# SERDES_10G0 register map
Vendor: Texas Instruments
Registers are 32-bit, access per field, reset 0x0 unless marked. A register's access mark holds for its fields unless they carry their own. Offsets are as the file gives them; [hi:lo] are bit positions.

## SERDES_10G0 (part 7 of 8)
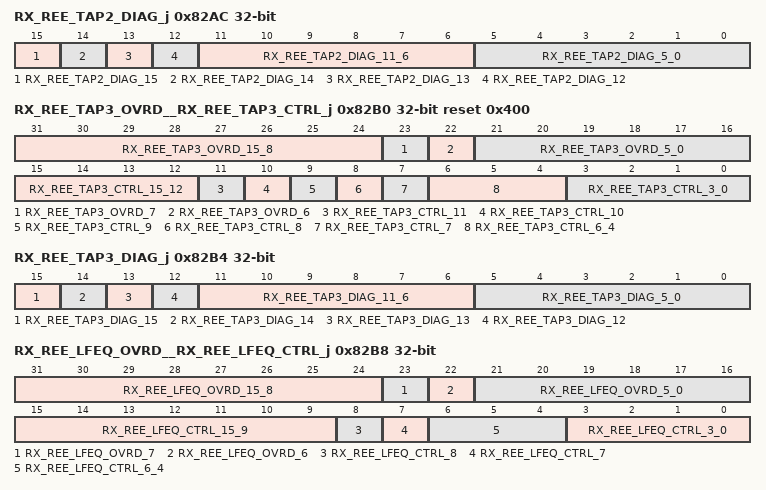
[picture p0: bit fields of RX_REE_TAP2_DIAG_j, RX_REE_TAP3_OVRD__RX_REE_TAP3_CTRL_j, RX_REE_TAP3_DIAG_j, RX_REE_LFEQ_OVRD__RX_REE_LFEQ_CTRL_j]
0x82AC RX_REE_TAP2_DIAG_j — REE tap 2 diagnostics register Offset = 82ACh + (j * 400h); where j = 0h to 3h
  [15] RX_REE_TAP2_DIAG_15 ro — Reserved
  [14] RX_REE_TAP2_DIAG_14 rw — Voter override neg : Writing a 1'b1 in this register bit will force the tap voter function to activate the voter neg signal for a single clock cycle.
  [13] RX_REE_TAP2_DIAG_13 rw — Voter override pos : Writing a 1'b1 in this register bit will force the tap voter function to activate the voter pos signal for a single clock cycle.
  [12] RX_REE_TAP2_DIAG_12 rw — Voter override enable : Setting this bit to a 1'b1 will allow only the voter override pos and voter override neg bits in this register to control the voter in the tap.
  [11:6] RX_REE_TAP2_DIAG_11_6 ro — Reserved
  [5:0] RX_REE_TAP2_DIAG_5_0 ro — Current tap integrator accumulator: Current value of the tap integrator accumulator.
0x82B0 RX_REE_TAP3_OVRD__RX_REE_TAP3_CTRL_j reset 0x400 — REE tap 3 control register Offset = 82B0h + (j * 400h); where j = 0h to 3h
  [31:24] RX_REE_TAP3_OVRD_15_8 ro — Reserved
  [23] RX_REE_TAP3_OVRD_7 rw — Tap override enable: Setting this bit to a 1'b1 will enable the tap override field in this register to override the tap integrator accumulator functions.
  [22] RX_REE_TAP3_OVRD_6 ro — Reserved
  [21:16] RX_REE_TAP3_OVRD_5_0 rw — Tap override value: When the tap override enable bit in this register is active, the value in this field will override the integrator accumulator value, as well as the input to the binary to thermometer encoder.
  [15:12] RX_REE_TAP3_CTRL_15_12 ro — Reserved
  [11] RX_REE_TAP3_CTRL_11 rw — Tap coefficient combinational logic zero crossing enable:
  [10] RX_REE_TAP3_CTRL_10 rw — Tap coefficient combinational logic non zero crossing enable:
  [9] RX_REE_TAP3_CTRL_9 rw — Tap coefficient combinational logic bit 0 only enable:
  [8] RX_REE_TAP3_CTRL_8 rw — Receiver DFE tap coefficient disable: This bit disables the rxda_dfe_tap_coef output signal.
  [7] RX_REE_TAP3_CTRL_7 ro — Reserved
  [6:4] RX_REE_TAP3_CTRL_6_4 rw — Tap integrator accumulator scaler value: Specifies the amount to scale the input to the tap integrator accumulator by.
  [3:0] RX_REE_TAP3_CTRL_3_0 rw — Tap sigma delta accumulator scaler value: Specifies the amount to scale the input to the tap sigma delta accumulator by.
0x82B4 RX_REE_TAP3_DIAG_j — REE tap 3 diagnostics register Offset = 82B4h + (j * 400h); where j = 0h to 3h
  [15] RX_REE_TAP3_DIAG_15 ro — Reserved
  [14] RX_REE_TAP3_DIAG_14 rw — Voter override neg : Writing a 1'b1 in this register bit will force the tap voter function to activate the voter neg signal for a single clock cycle.
  [13] RX_REE_TAP3_DIAG_13 rw — Voter override pos : Writing a 1'b1 in this register bit will force the tap voter function to activate the voter pos signal for a single clock cycle.
  [12] RX_REE_TAP3_DIAG_12 rw — Voter override enable : Setting this bit to a 1'b1 will allow only the voter override pos and voter override neg bits in this register to control the voter in the tap.
  [11:6] RX_REE_TAP3_DIAG_11_6 ro — Reserved
  [5:0] RX_REE_TAP3_DIAG_5_0 ro — Current tap integrator accumulator: Current value of the tap integrator accumulator.
0x82B8 RX_REE_LFEQ_OVRD__RX_REE_LFEQ_CTRL_j — REE low frequency equalizer control register Offset = 82B8h + (j * 400h); where j = 0h to 3h
  [31:24] RX_REE_LFEQ_OVRD_15_8 ro — Reserved
  [23] RX_REE_LFEQ_OVRD_7 rw — Override enable: Setting this bit to a 1'b1 will enable the override field in this register to override the integrator accumulator functions.
  [22] RX_REE_LFEQ_OVRD_6 ro — Reserved
  [21:16] RX_REE_LFEQ_OVRD_5_0 rw — Override value: When the override enable bit in this register is active, the value in this field will override the integrator accumulator value, as well as the input to the binary to thermometer encoder.
  [15:9] RX_REE_LFEQ_CTRL_15_9 ro — Reserved
  [8] RX_REE_LFEQ_CTRL_8 rw — Receiver DFE coefficient disable: This bit disables the rxda_dfe_coef output signal.
  [7] RX_REE_LFEQ_CTRL_7 ro — Reserved
  [6:4] RX_REE_LFEQ_CTRL_6_4 rw — Integrator accumulator scaler value: Specifies the amount to scale the input to the integrator accumulator by.
  [3:0] RX_REE_LFEQ_CTRL_3_0 rw — Sigma delta accumulator scaler value: Specifies the amount to scale the input to the sigma delta accumulator by.
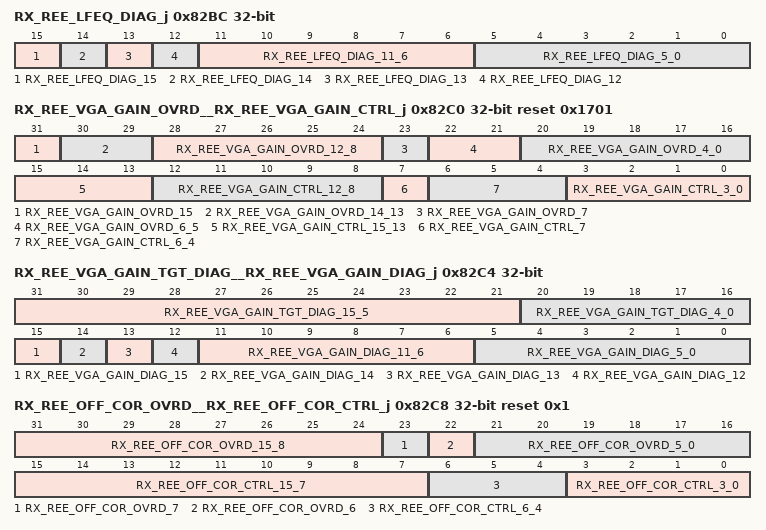
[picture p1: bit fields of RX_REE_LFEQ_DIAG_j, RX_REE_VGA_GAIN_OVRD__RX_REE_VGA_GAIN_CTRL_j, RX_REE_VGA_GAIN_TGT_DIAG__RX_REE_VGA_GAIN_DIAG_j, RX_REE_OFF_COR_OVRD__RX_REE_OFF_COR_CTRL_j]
0x82BC RX_REE_LFEQ_DIAG_j — REE low frequency equalizer diagnostics register Offset = 82BCh + (j * 400h); where j = 0h to 3h
  [15] RX_REE_LFEQ_DIAG_15 ro — Reserved
  [14] RX_REE_LFEQ_DIAG_14 rw — Voter override neg : Writing a 1'b1 in this register bit will force the voter function to activate the voter neg signal for a single clock cycle.
  [13] RX_REE_LFEQ_DIAG_13 rw — Voter override pos : Writing a 1'b1 in this register bit will force the voter function to activate the voter pos signal for a single cycle.
  [12] RX_REE_LFEQ_DIAG_12 rw — Voter override enable : Setting this bit to a 1'b1 will allow only the voter override pos and voter override neg bits in this register to control the voter.
  [11:6] RX_REE_LFEQ_DIAG_11_6 ro — Reserved
  [5:0] RX_REE_LFEQ_DIAG_5_0 ro — Current integrator accumulator: Current value of the integrator accumulator.
0x82C0 RX_REE_VGA_GAIN_OVRD__RX_REE_VGA_GAIN_CTRL_j reset 0x1701 — REE VGA gain control register Offset = 82C0h + (j * 400h); where j = 0h to 3h
  [31] RX_REE_VGA_GAIN_OVRD_15 rw — VGA gain target adjust override enable: Setting this bit to a 1'b1 will enable the VGA gain target adjust override field in this register to override the VGA gain target adjust accumulator functions.
  [30:29] RX_REE_VGA_GAIN_OVRD_14_13 ro — Reserved
  [28:24] RX_REE_VGA_GAIN_OVRD_12_8 rw — VGA gain target adjust override value: When the VGA gain target adjust override enable bit in this register is active, the value in this field will override the accumulator value used to drive the vga_gain_tgt_adj signal.
  [23] RX_REE_VGA_GAIN_OVRD_7 rw — VGA gain override enable: Setting this bit to a 1'b1 will enable the VGA gain override field in this register to override the VGA gain integrator accumulator functions.
  [22:21] RX_REE_VGA_GAIN_OVRD_6_5 ro — Reserved
  [20:16] RX_REE_VGA_GAIN_OVRD_4_0 rw — VGA gain override value: When the VGA gain override enable bit in this register is active, the value in this field will override the integrator accumulator value, as well as the input to the binary to thermometer encoder.
  [15:13] RX_REE_VGA_GAIN_CTRL_15_13 ro — Reserved
  [12:8] RX_REE_VGA_GAIN_CTRL_12_8 rw — VGA gain max: Specifies the maximum value of the VGA gain integrator accumulator, and therefore also the maximum number of bits in the rxda_dfe_vga_gain thermometer code that will be set.
  [7] RX_REE_VGA_GAIN_CTRL_7 ro — Reserved
  [6:4] RX_REE_VGA_GAIN_CTRL_6_4 rw — VGA gain integrator accumulator scaler value: Specifies the amount to scale the input to the VGA gain integrator accumulator by.
  [3:0] RX_REE_VGA_GAIN_CTRL_3_0 rw — VGA gain sigma delta accumulator scaler value: Specifies the amount to scale the input to the VGA gain sigma delta accumulator by.
0x82C4 RX_REE_VGA_GAIN_TGT_DIAG__RX_REE_VGA_GAIN_DIAG_j — REE VGA gain diagnostics register Offset = 82C4h + (j * 400h); where j = 0h to 3h
  [31:21] RX_REE_VGA_GAIN_TGT_DIAG_15_5 ro — Reserved
  [20:16] RX_REE_VGA_GAIN_TGT_DIAG_4_0 ro — Current VGA gain integrator accumulator: Current value of the VGA gain integrator accumulator.
  [15] RX_REE_VGA_GAIN_DIAG_15 ro — Reserved
  [14] RX_REE_VGA_GAIN_DIAG_14 rw — Voter override neg : Writing a 1'b1 in this register bit will force the VGA gain voter function to activate the voter neg signal for a single clock cycle.
  [13] RX_REE_VGA_GAIN_DIAG_13 rw — Voter override pos : Writing a 1'b1 in this register bit will force the VGA gain voter function to activate the voter pos signal for a single clock cycle.
  [12] RX_REE_VGA_GAIN_DIAG_12 rw — Voter override enable : Setting this bit to a 1'b1 will allow only the voter override pos and voter override neg bits in this register to control the voter in the VGA gain.
  [11:6] RX_REE_VGA_GAIN_DIAG_11_6 ro — Reserved
  [5:0] RX_REE_VGA_GAIN_DIAG_5_0 ro — Current VGA gain integrator accumulator: Current value of the VGA gain integrator accumulator.
0x82C8 RX_REE_OFF_COR_OVRD__RX_REE_OFF_COR_CTRL_j reset 0x1 — REE offset correction control register Offset = 82C8h + (j * 400h); where j = 0h to 3h
  [31:24] RX_REE_OFF_COR_OVRD_15_8 ro — Reserved
  [23] RX_REE_OFF_COR_OVRD_7 rw — Offset correction override enable: Setting this bit to a 1'b1 will enable the offset correction override field in this register to override the offset correction integrator accumulator functions.
  [22] RX_REE_OFF_COR_OVRD_6 ro — Reserved
  [21:16] RX_REE_OFF_COR_OVRD_5_0 rw — Offset correction override value: When the offset correction override enable bit in this register is active, the value in this field will override the integrator accumulator value, as well as the input to the binary to thermometer encoder.
  [15:7] RX_REE_OFF_COR_CTRL_15_7 ro — Reserved
  [6:4] RX_REE_OFF_COR_CTRL_6_4 rw — Offset correction integrator accumulator scaler value: Specifies the amount to scale the input to the offset correction integrator accumulator by.
  [3:0] RX_REE_OFF_COR_CTRL_3_0 rw — Offset correction sigma delta accumulator scaler value: Specifies the amount to scale the input to the offset correction sigma delta accumulator by.
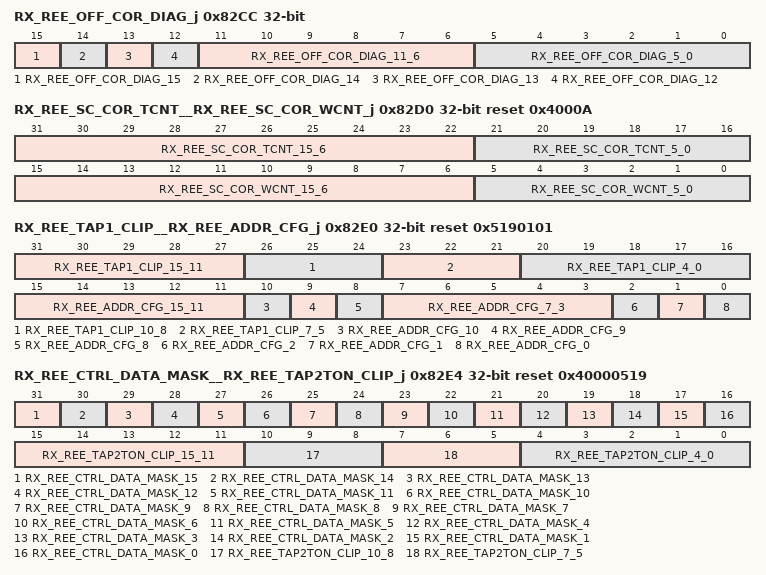
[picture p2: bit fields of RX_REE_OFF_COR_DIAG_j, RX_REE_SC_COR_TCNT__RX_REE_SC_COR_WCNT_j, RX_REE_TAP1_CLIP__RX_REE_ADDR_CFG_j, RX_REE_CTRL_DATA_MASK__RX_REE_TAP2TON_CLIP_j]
0x82CC RX_REE_OFF_COR_DIAG_j — REE offset correction diagnostics register Offset = 82CCh + (j * 400h); where j = 0h to 3h
  [15] RX_REE_OFF_COR_DIAG_15 ro — Reserved
  [14] RX_REE_OFF_COR_DIAG_14 rw — Voter override neg : Writing a 1'b1 in this register bit will force the offset correction voter function to activate the voter neg signal for a single clock cycle.
  [13] RX_REE_OFF_COR_DIAG_13 rw — Voter override pos : Writing a 1'b1 in this register bit will force the offset correction voter function to activate the voter pos signal for a single clock cycle.
  [12] RX_REE_OFF_COR_DIAG_12 rw — Voter override enable : Setting this bit to a 1'b1 will allow only the voter override pos and voter override neg bits in this register to control the voter in the offset correction.
  [11:6] RX_REE_OFF_COR_DIAG_11_6 ro — Reserved
  [5:0] RX_REE_OFF_COR_DIAG_5_0 ro — Current offset correction integrator accumulator: Current value of the offset correction integrator accumulator.
0x82D0 RX_REE_SC_COR_TCNT__RX_REE_SC_COR_WCNT_j reset 0x4000A — REE short channel correction valid word counter register Offset = 82D0h + (j * 400h); where j = 0h to 3h
  [31:22] RX_REE_SC_COR_TCNT_15_6 ro — Reserved
  [21:16] RX_REE_SC_COR_TCNT_5_0 rw — Threshold counter start value : Value used for the starting value when counting the number of bits that are below the error threshold.
  [15:6] RX_REE_SC_COR_WCNT_15_6 ro — Reserved
  [5:0] RX_REE_SC_COR_WCNT_5_0 rw — Valid word counter start value : Value used for the starting value when counting the number of valid words.
0x82E0 RX_REE_TAP1_CLIP__RX_REE_ADDR_CFG_j reset 0x5190101 — REE adder configuration register Offset = 82E0h + (j * 400h); where j = 0h to 3h
  [31:27] RX_REE_TAP1_CLIP_15_11 ro — Reserved
  [26:24] RX_REE_TAP1_CLIP_10_8 rw — VGA target gain adjust multiplier: Controls how much to multiply the VGA target gain adjust by, when calculating the tap threshold.
  [23:21] RX_REE_TAP1_CLIP_7_5 ro — Reserved
  [20:16] RX_REE_TAP1_CLIP_4_0 rw — Threshold adjust: Controls how much the threshold can be adjusted by, after multiplying the VGA target gain adjust multiplier with the VGA target gain adjust.
  [15:11] RX_REE_ADDR_CFG_15_11 ro — Reserved
  [10] RX_REE_ADDR_CFG_10 rw — TX post cursor tap 3 adder enable: Setting this bit to 1'b1, enables the results of tap 3 to be added to the TX post cursor controller input.
  [9] RX_REE_ADDR_CFG_9 rw — TX post cursor tap 2 adder enable: Setting this bit to 1'b1, enables the results of tap 2 to be added to the TX post cursor controller input.
  [8] RX_REE_ADDR_CFG_8 rw — TX post cursor tap 1 adder enable: Setting this bit to 1'b1, enables the results of tap 1 to be added to the TX post cursor controller input.
  [7:3] RX_REE_ADDR_CFG_7_3 ro — Reserved
  [2] RX_REE_ADDR_CFG_2 rw — RX peaking tap 3 adder enable: Setting this bit to 1'b1, enables the results of tap 3 to be added to the RX peaking amp gain input.
  [1] RX_REE_ADDR_CFG_1 rw — RX peaking tap 2 adder enable: Setting this bit to 1'b1, enables the results of tap 2 to be added to the RX peaking amp gain input.
  [0] RX_REE_ADDR_CFG_0 rw — RX peaking tap 1 adder enable: Setting this bit to 1'b1, enables the results of tap 1 to be added to the RX peaking amp gain input.
0x82E4 RX_REE_CTRL_DATA_MASK__RX_REE_TAP2TON_CLIP_j reset 0x40000519 — REE taps 2 and 3 clip control register Offset = 82E4h + (j * 400h); where j = 0h to 3h
  [31] RX_REE_CTRL_DATA_MASK_15 ro — Reserved
  [30] RX_REE_CTRL_DATA_MASK_14 ro — Ignore 1010 controller - Note that this is read only.
  [29] RX_REE_CTRL_DATA_MASK_13 rw — TX equalization evaluator: When set to 1'b0, this REE component will be turned off when control data is being received, when either the rx_eq_training_data_valid signal going inactive, or a 1010 pattern is detected on the data signals by the REE.
  [28] RX_REE_CTRL_DATA_MASK_12 rw — TX post cursor control: When set to 1'b0, this REE component will be turned off when control data is being received, when either the rx_eq_training_data_valid signal going inactive, or a 1010 pattern is detected on the data signals by the REE.
  [27] RX_REE_CTRL_DATA_MASK_11 rw — TX pre cursor control: When set to 1'b0, this REE component will be turned off when control data is being received, when either the rx_eq_training_data_valid signal going inactive, or a 1010 pattern is detected on the data signals by the REE.
  [26] RX_REE_CTRL_DATA_MASK_10 rw — Short channel correction: When set to 1'b0, this REE component will be turned off when control data is being received, when either the rx_eq_training_data_valid signal going inactive, or a 1010 pattern is detected on the data signals by the REE.
  [25] RX_REE_CTRL_DATA_MASK_9 rw — RX attenuation: When set to 1'b0, this REE component will be turned off when control data is being received, when either the rx_eq_training_data_valid signal going inactive, or a 1010 pattern is detected on the data signals by the REE.
  [24] RX_REE_CTRL_DATA_MASK_8 rw — RX VGA gain: When set to 1'b0, this REE component will be turned off when control data is being received, when either the rx_eq_training_data_valid signal going inactive, or a 1010 pattern is detected on the data signals by the REE.
  [23] RX_REE_CTRL_DATA_MASK_7 rw — RX offset correction coefficient: When set to 1'b0, this REE component will be turned off when control data is being received, when either the rx_eq_training_data_valid signal going inactive, or a 1010 pattern is detected on the data signals by the REE.
  [22] RX_REE_CTRL_DATA_MASK_6 rw — RX peaking amp gain: When set to 1'b0, this REE component will be turned off when control data is being received, when either the rx_eq_training_data_valid signal going inactive, or a 1010 pattern is detected on the data signals by the REE.
  [21] RX_REE_CTRL_DATA_MASK_5 rw — RX low frequency equalizer adaptive control: When set to 1'b0, this REE component will be turned off when control data is being received, when either the rx_eq_training_data_valid signal going inactive, or a 1010 pattern is detected on the data signals by the REE.
  [20] RX_REE_CTRL_DATA_MASK_4 ro — Reserved
  [19] RX_REE_CTRL_DATA_MASK_3 ro — Reserved
  [18] RX_REE_CTRL_DATA_MASK_2 rw — RX tap 3: When set to 1'b0, this REE component will be turned off when control data is being received, when either the rx_eq_training_data_valid signal going inactive, or a 1010 pattern is detected on the data signals by the REE.
  [17] RX_REE_CTRL_DATA_MASK_1 rw — RX tap 2: When set to 1'b0, this REE component will be turned off when control data is being received, when either the rx_eq_training_data_valid signal going inactive, or a 1010 pattern is detected on the data signals by the REE.
  [16] RX_REE_CTRL_DATA_MASK_0 rw — RX tap 1: When set to 1'b0, this REE component will be turned off when control data is being received, when either the rx_eq_training_data_valid signal going inactive, or a 1010 pattern is detected on the data signals by the REE.
  [15:11] RX_REE_TAP2TON_CLIP_15_11 ro — Reserved
  [10:8] RX_REE_TAP2TON_CLIP_10_8 rw — VGA target gain adjust multiplier: Controls how much to multiply the VGA target gain adjust by, when calculating the tap threshold.
  [7:5] RX_REE_TAP2TON_CLIP_7_5 ro — Reserved
  [4:0] RX_REE_TAP2TON_CLIP_4_0 rw — Threshold adjust: Controls how much the threshold can be adjusted by, after multiplying the VGA target gain adjust multiplier with the VGA target gain adjust.
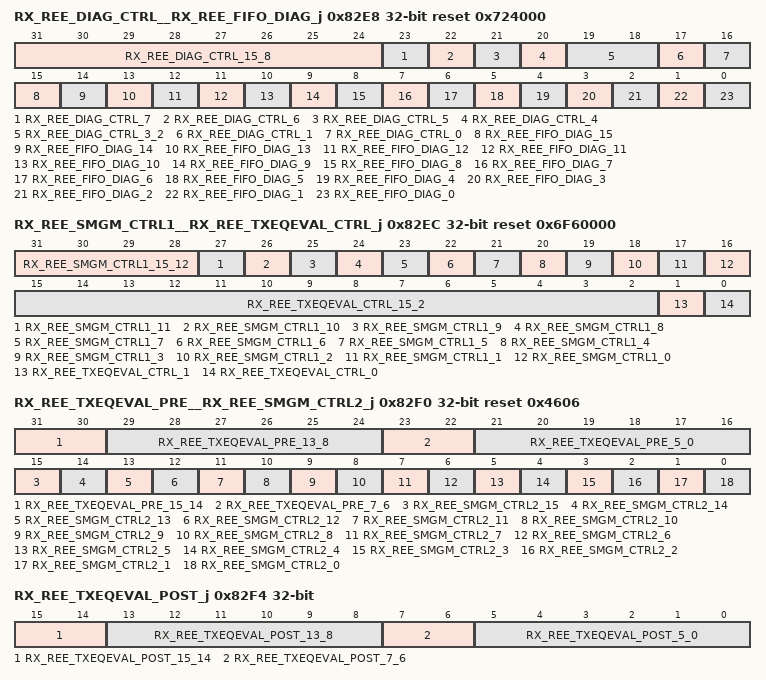
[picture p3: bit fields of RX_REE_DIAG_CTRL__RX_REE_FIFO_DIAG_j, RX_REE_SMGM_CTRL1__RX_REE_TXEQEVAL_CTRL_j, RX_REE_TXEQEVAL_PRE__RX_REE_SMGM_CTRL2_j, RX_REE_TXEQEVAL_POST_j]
0x82E8 RX_REE_DIAG_CTRL__RX_REE_FIFO_DIAG_j reset 0x724000 — REE coefficient FIFO diagnostic register Offset = 82E8h + (j * 400h); where j = 0h to 3h
  [31:24] RX_REE_DIAG_CTRL_15_8 ro — Reserved
  [23] RX_REE_DIAG_CTRL_7 rw — Analog tap disable: When this bit is set to 1'b1, the rxda_dfe_tap_1_coef, rxda_dfe_tap_2_coef, and rxda_dfe_tap_3_coef signals being driven to the analog will be forced to all 0s.
  [22] RX_REE_DIAG_CTRL_6 rw — Hold periodic equalization while RX idle: When this bit is set to 1'b1, a detection of electrical idle on the receiver (rx_signal_detect is set to 1'b0), will disable the periodic REE general control state machine, and as a result freeze the current state of the parts of the REE that are controlled by it.
  [21] RX_REE_DIAG_CTRL_5 rw — Hold general control state machine 2 equalization while RX idle: When this bit is set to 1'b1, a detection of electrical idle on the receiver (rx_signal_detect is set to 1'b0), will disable the REE general control state machine 2, and as a result freeze the current state of the parts of the REE that are controlled by it.
  [20] RX_REE_DIAG_CTRL_4 rw — Hold general control state machine 1 equalization while RX idle: When this bit is set to 1'b1, a detection of electrical idle on the receiver (rx_signal_detect is set to 1'b0), will disable the REE general control state machine 1, and as a result freeze the current state of the parts of the REE that are controlled by it.
  [19:18] RX_REE_DIAG_CTRL_3_2 ro — Reserved
  [17] RX_REE_DIAG_CTRL_1 rw — Enable REE control clock on : Enables the REE control clock.
  [16] RX_REE_DIAG_CTRL_0 rw — Force REE function clock on : When active, the REE function clock gate will allow the clock to run.
  [15] RX_REE_FIFO_DIAG_15 ro — FIFO underflow : Indicates when a FIFO underflow condition has occurred.
  [14] RX_REE_FIFO_DIAG_14 ro — FIFO empty :Indicates that the FIFO is empty.
  [13] RX_REE_FIFO_DIAG_13 rw — FIFO output dequeue : Writing a 1'b1 to this bit will dequeue the current values from the output of the FIFO.
  [12] RX_REE_FIFO_DIAG_12 rw — FIFO output override enable : Enables the FIFO output override functions.
  [11] RX_REE_FIFO_DIAG_11 ro — FIFO output data pre cursor increment : Current value on the pre cursor increment bit on the FIFO output.
  [10] RX_REE_FIFO_DIAG_10 ro — FIFO output data pre cursor decrement : Current value on the pre cursor decrement bit on the FIFO output.
  [9] RX_REE_FIFO_DIAG_9 ro — FIFO output data post cursor increment : Current value on the post cursor increment bit on the FIFO output.
  [8] RX_REE_FIFO_DIAG_8 ro — FIFO output data post cursor decrement : Current value on the post cursor decrement bit on the FIFO output.
  [7] RX_REE_FIFO_DIAG_7 ro — FIFO overflow :Indicates when a FIFO overflow condition has occurred.
  [6] RX_REE_FIFO_DIAG_6 ro — FIFO full :Indicates that the FIFO is full.
  [5] RX_REE_FIFO_DIAG_5 rw — FIFO input enqueue : Writing a 1'b1 to this bit will enqueue the values of the FIFO input data bits in this register to their respective FIFO bits.
  [4] RX_REE_FIFO_DIAG_4 rw — FIFO input override enable : Enables the FIFO input override functions.
  [3] RX_REE_FIFO_DIAG_3 rw — FIFO input data pre cursor increment : Pre cursor increment value that will be enqueued to the FIFO by the FIFO input enqueue bit in this register.
  [2] RX_REE_FIFO_DIAG_2 rw — FIFO input data pre cursor decrement : Pre cursor decrement value that will be enqueued to the FIFO by the FIFO input enqueue bit in this register.
  [1] RX_REE_FIFO_DIAG_1 rw — FIFO input data post cursor increment : Post cursor increment value that will be enqueued to the FIFO by the FIFO input enqueue bit in this register.
  [0] RX_REE_FIFO_DIAG_0 rw — FIFO input data post cursor decrement : Post cursor decrement value that will be enqueued to the FIFO by the FIFO input enqueue bit in this register.
0x82EC RX_REE_SMGM_CTRL1__RX_REE_TXEQEVAL_CTRL_j reset 0x6F60000 — REE TX equalization evaluator control register Offset = 82ECh + (j * 400h); where j = 0h to 3h
  [31:28] RX_REE_SMGM_CTRL1_15_12 ro — Reserved
  [27] RX_REE_SMGM_CTRL1_11 rw — REE Periodic general control state machine enable standard mode 3: This bit will control if the REE periodic general control state machine will run, when xcvr_standard_mode is set to 2'b11.
  [26] RX_REE_SMGM_CTRL1_10 rw — REE Periodic general control state machine enable standard mode 2: This bit will control if the REE periodic general control state machine will run, when xcvr_standard_mode is set to 2'b10.
  [25] RX_REE_SMGM_CTRL1_9 rw — REE Periodic general control state machine enable standard mode 1: This bit will control if the REE periodic general control state machine will run, when xcvr_standard_mode is set to 2'b01.
  [24] RX_REE_SMGM_CTRL1_8 rw — REE Periodic general control state machine enable standard mode 0: This bit will control if the REE periodic general control state machine will run, when xcvr_standard_mode is set to 2'b00.
  [23] RX_REE_SMGM_CTRL1_7 rw — REE general control state machine 2 enable standard mode 3: This bit will control if the REE general control state machine 2 will run, when xcvr_standard_mode is set to 2'b11.
  [22] RX_REE_SMGM_CTRL1_6 rw — REE general control state machine 2 enable standard mode 2: This bit will control if the REE general control state machine 2 will run, when xcvr_standard_mode is set to 2'b10.
  [21] RX_REE_SMGM_CTRL1_5 rw — REE general control state machine 2 enable standard mode 1: This bit will control if the REE general control state machine 2 will run, when xcvr_standard_mode is set to 2'b01.
  [20] RX_REE_SMGM_CTRL1_4 rw — REE general control state machine 2 enable standard mode 0: This bit will control if the REE general control state machine 2 will run, when xcvr_standard_mode is set to 2'b00.
  [19] RX_REE_SMGM_CTRL1_3 rw — REE general control state machine 1 enable standard mode 3: This bit will control if the REE general control state machine 1 will run, when xcvr_standard_mode is set to 2'b11.
  [18] RX_REE_SMGM_CTRL1_2 rw — REE general control state machine 1 enable standard mode 2: This bit will control if the REE general control state machine 1 will run, when xcvr_standard_mode is set to 2'b10.
  [17] RX_REE_SMGM_CTRL1_1 rw — REE general control state machine 1 enable standard mode 1: This bit will control if the REE general control state machine 1 will run, when xcvr_standard_mode is set to 2'b01.
  [16] RX_REE_SMGM_CTRL1_0 rw — REE general control state machine 1 enable standard mode 0: This bit will control if the REE general control state machine 1 will run, when xcvr_standard_mode is set to 2'b00.
  [15:2] RX_REE_TXEQEVAL_CTRL_15_2 ro — Reserved
  [1] RX_REE_TXEQEVAL_CTRL_1 rw — TX equalization evaluation counter reset on gen mode change: Controls if the incremental evaluation counter will be reset to its starting value when changing gen modes.
  [0] RX_REE_TXEQEVAL_CTRL_0 rw — TX main coefficient direction change control: This bit controls the function of the main coefficient direction change.
0x82F0 RX_REE_TXEQEVAL_PRE__RX_REE_SMGM_CTRL2_j reset 0x4606 — REE control state machine gen mode control register 2 Offset = 82F0h + (j * 400h); where j = 0h to 3h
  [31:30] RX_REE_TXEQEVAL_PRE_15_14 ro — Reserved
  [29:24] RX_REE_TXEQEVAL_PRE_13_8 ro — TX equalization evaluator pre-emphasis increment count: Contains a count of the total number of pre-emphasis increment responses that have taken place during the TX equalization evaluator process.
  [23:22] RX_REE_TXEQEVAL_PRE_7_6 ro — Reserved
  [21:16] RX_REE_TXEQEVAL_PRE_5_0 ro — TX equalization evaluator pre-emphasis decrement count: Contains a count of the total number of pre-emphasis decrement responses that have taken place during the TX equalization evaluator process.
  [15] RX_REE_SMGM_CTRL2_15 rw — REE PCIe Gen 3 TX equalization state machine E path en standard mode 3: This bit controls if the REE PCIE Gen 3 TX equalization state machine will enable the analog E path when xcvr_standard_mode is set to 2'b11.
  [14] RX_REE_SMGM_CTRL2_14 rw — REE PCIe Gen 3 TX equalization state machine E path en standard mode 2: This bit controls if the REE PCIE Gen 3 TX equalization state machine will enable the analog E path when xcvr_standard_mode is set to 2'b10.
  [13] RX_REE_SMGM_CTRL2_13 rw — REE PCIe Gen 3 TX equalization state machine E path en standard mode 1: This bit controls if the REE PCIE Gen 3 TX equalization state machine will enable the analog E path when xcvr_standard_mode is set to 2'b01.
  [12] RX_REE_SMGM_CTRL2_12 rw — REE PCIe Gen 3 TX equalization state machine E path en standard mode 0: This bit controls if the REE PCIE Gen 3 TX equalization state machine will enable the analog E path when xcvr_standard_mode is set to 2'b00.
  [11] RX_REE_SMGM_CTRL2_11 rw — REE Periodic general control state machine E path en standard mode 3: This bit controls if the REE periodic general control state machine will enable the analog E path when xcvr_standard_mode is set to 2'b11.
  [10] RX_REE_SMGM_CTRL2_10 rw — REE Periodic general control state machine E path en standard mode 2: This bit controls if the REE periodic general control state machine will enable the analog E path when xcvr_standard_mode is set to 2'b10.
  [9] RX_REE_SMGM_CTRL2_9 rw — REE Periodic general control state machine E path en standard mode 1: This bit controls if the REE periodic general control state machine will enable the analog E path when xcvr_standard_mode is set to 2'b01.
  [8] RX_REE_SMGM_CTRL2_8 rw — REE Periodic general control state machine E path en standard mode 0: This bit controls if the REE periodic general control state machine will enable the analog E path when xcvr_standard_mode is set to 2'b00.
  [7] RX_REE_SMGM_CTRL2_7 rw — REE general control state machine 2 E path en standard mode 3: This bit controls if the REE general control state machine 2 will enable the analog E path when xcvr_standard_mode is set to 2'b11.
  [6] RX_REE_SMGM_CTRL2_6 rw — REE general control state machine 2 E path en standard mode 2: This bit controls if the REE general control state machine 2 will enable the analog E path when xcvr_standard_mode is set to 2'b10.
  [5] RX_REE_SMGM_CTRL2_5 rw — REE general control state machine 2 E path en standard mode 1: This bit controls if the REE general control state machine 2 will enable the analog E path when xcvr_standard_mode is set to 2'b01.
  [4] RX_REE_SMGM_CTRL2_4 rw — REE general control state machine 2 E path en standard mode 0: This bit controls if the REE general control state machine 2 will enable the analog E path when xcvr_standard_mode is set to 2'b00.
  [3] RX_REE_SMGM_CTRL2_3 rw — REE general control state machine 1 E path en standard mode 3: This bit controls if the REE general control state machine 1 will enable the analog E path when xcvr_standard_mode is set to 2'b11.
  [2] RX_REE_SMGM_CTRL2_2 rw — REE general control state machine 1 E path en standard mode 2: This bit controls if the REE general control state machine 1 will enable the analog E path when xcvr_standard_mode is set to 2'b10.
  [1] RX_REE_SMGM_CTRL2_1 rw — REE general control state machine 1 E path en standard mode 1: This bit controls if the REE general control state machine 1 will enable the analog E path when xcvr_standard_mode is set to 2'b01.
  [0] RX_REE_SMGM_CTRL2_0 rw — REE general control state machine 1 E path en standard mode 0: This bit controls if the REE general control state machine 1 will enable the analog E path when xcvr_standard_mode is set to 2'b00.
0x82F4 RX_REE_TXEQEVAL_POST_j ro — REE TX equalization evaluator post-emphasis register Offset = 82F4h + (j * 400h); where j = 0h to 3h
  [15:14] RX_REE_TXEQEVAL_POST_15_14 — Reserved
  [13:8] RX_REE_TXEQEVAL_POST_13_8 — TX equalization evaluator post-emphasis increment count: Contains a count of the total number of post-emphasis increment responses that have taken place during the TX equalization evaluator process.
  [7:6] RX_REE_TXEQEVAL_POST_7_6 — Reserved
  [5:0] RX_REE_TXEQEVAL_POST_5_0 — TX equalization evaluator post-emphasis decrement count: Contains a count of the total number of post-emphasis decrement responses that have taken place during the TX equalization evaluator process.
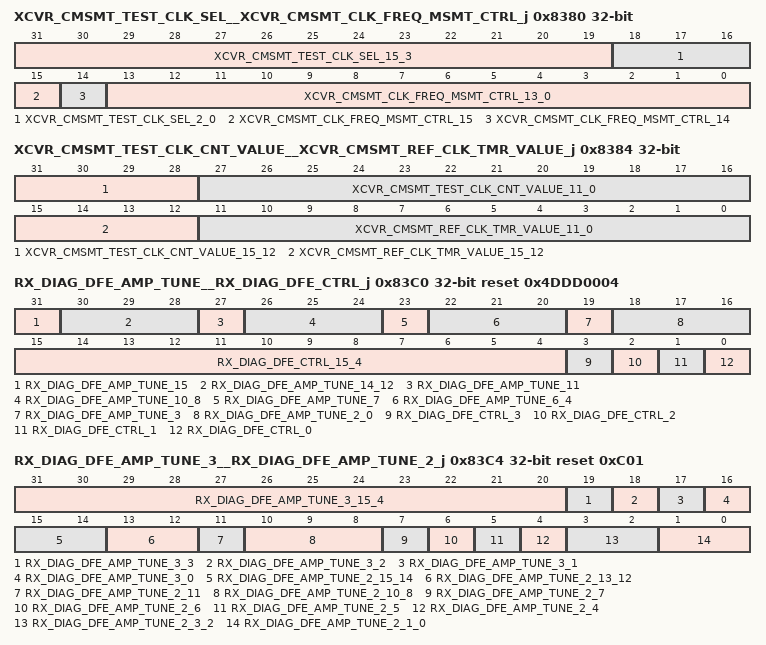
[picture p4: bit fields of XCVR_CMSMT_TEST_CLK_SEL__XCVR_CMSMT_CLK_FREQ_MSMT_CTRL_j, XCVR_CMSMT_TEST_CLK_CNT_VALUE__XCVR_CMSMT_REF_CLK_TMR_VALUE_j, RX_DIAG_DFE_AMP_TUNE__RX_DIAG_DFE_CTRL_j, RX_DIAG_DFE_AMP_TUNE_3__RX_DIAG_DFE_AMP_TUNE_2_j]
0x8380 XCVR_CMSMT_TEST_CLK_SEL__XCVR_CMSMT_CLK_FREQ_MSMT_CTRL_j — Clock frequency measurement control register Offset = 8380h + (j * 400h); where j = 0h to 3h
  [31:19] XCVR_CMSMT_TEST_CLK_SEL_15_3 ro — Reserved
  [18:16] XCVR_CMSMT_TEST_CLK_SEL_2_0 rw — Test clock select: This field drives the test_clk_select pin, in order to control an external MUX for selecting between multiple test clocks to measure.
  [15] XCVR_CMSMT_CLK_FREQ_MSMT_CTRL_15 rw — Run test clock measurement: Activating (1'b1) this bit will run the test clock measurement process.
  [14] XCVR_CMSMT_CLK_FREQ_MSMT_CTRL_14 ro — Test clock measurement done: This bit will be set to 1'b1 when the test clock measurement process is complete.
  [13:0] XCVR_CMSMT_CLK_FREQ_MSMT_CTRL_13_0 ro — Reserved
0x8384 XCVR_CMSMT_TEST_CLK_CNT_VALUE__XCVR_CMSMT_REF_CLK_TMR_VALUE_j — Reference clock timer value register Offset = 8384h + (j * 400h); where j = 0h to 3h
  [31:28] XCVR_CMSMT_TEST_CLK_CNT_VALUE_15_12 ro — Reserved
  [27:16] XCVR_CMSMT_TEST_CLK_CNT_VALUE_11_0 ro — Test clock counter value: When the test clock measurement process is complete, the value in this field specifies the number of test clock cycles that were counted in the time specified by the reference clock timer value.
  [15:12] XCVR_CMSMT_REF_CLK_TMR_VALUE_15_12 ro — Reserved
  [11:0] XCVR_CMSMT_REF_CLK_TMR_VALUE_11_0 rw — Reference clock timer value : This specifies the amount of time, in reference clock cycles, to count test clock cycles.
0x83C0 RX_DIAG_DFE_AMP_TUNE__RX_DIAG_DFE_CTRL_j reset 0x4DDD0004 — Receiver DFE control register Offset = 83C0h + (j * 400h); where j = 0h to 3h
  [31] RX_DIAG_DFE_AMP_TUNE_15 ro — Reserved
  [30:28] RX_DIAG_DFE_AMP_TUNE_14_12 rw — DFE constant gm bias tune: Adjusts the constant gm bias.
  [27] RX_DIAG_DFE_AMP_TUNE_11 rw — DFE VGA constant gm bias enable: Enables the VGA constant gm bias.
  [26:24] RX_DIAG_DFE_AMP_TUNE_10_8 rw — DFE VGA amp current adjust: Adjusts the current for the DFE VGA amp, using the rxda_vga_current_adj signal, as specified below.
  [23] RX_DIAG_DFE_AMP_TUNE_7 rw — DFE peaking constant gm bias enable: Enables the peaking constant gm bias.
  [22:20] RX_DIAG_DFE_AMP_TUNE_6_4 rw — DFE peaking amp current adjust: Adjusts the current for the DFE peaking amp, using the rxda_peak_current_adj signal, as specified below.
  [19] RX_DIAG_DFE_AMP_TUNE_3 rw — DFE summing constant gm bias enable: Enables the summing constant gm bias.
  [18:16] RX_DIAG_DFE_AMP_TUNE_2_0 rw — DFE summing amp current adjust: Adjusts the current for the DFE summing amp, using the rxda_sum_current_adj signal, as specified below.
  [15:4] RX_DIAG_DFE_CTRL_15_4 ro — Reserved
  [3] RX_DIAG_DFE_CTRL_3 rw — Receiver DFE low frequency equalization enable value standard mode 3: This bit controls the rxda_dfe_lfeq_en signal going to the analog, which is used to enable the receiver DFE low frequency equalization analog circuits, when xcvr_standard_mode is set to 2'b11.
  [2] RX_DIAG_DFE_CTRL_2 rw — Receiver DFE low frequency equalization enable value standard mode 2: This bit controls the rxda_dfe_lfeq_en signal going to the analog, which is used to enable the receiver DFE low frequency equalization analog circuits, when xcvr_standard_mode is set to 2'b10.
  [1] RX_DIAG_DFE_CTRL_1 rw — Receiver DFE low frequency equalization enable value standard mode 1: This bit controls the rxda_dfe_lfeq_en signal going to the analog, which is used to enable the receiver DFE low frequency equalization analog circuits, when xcvr_standard_mode is set to 2'b01.
  [0] RX_DIAG_DFE_CTRL_0 rw — Receiver DFE low frequency equalization enable value standard mode 0: This bit controls the rxda_dfe_lfeq_en signal going to the analog, which is used to enable the receiver DFE low frequency equalization analog circuits, when xcvr_standard_mode is set to 2'b00.
0x83C4 RX_DIAG_DFE_AMP_TUNE_3__RX_DIAG_DFE_AMP_TUNE_2_j reset 0xC01 — DFE amp fine tuning 2 register Offset = 83C4h + (j * 400h); where j = 0h to 3h
  [31:20] RX_DIAG_DFE_AMP_TUNE_3_15_4 ro — Reserved
  [19] RX_DIAG_DFE_AMP_TUNE_3_3 rw — DFE VGA stage 1 boost standard mode 3: This bit enables the active inductors boost function in stage 1 of the VGA, for high data rates, when xcvr_standard_mode is set to 2'b11.
  [18] RX_DIAG_DFE_AMP_TUNE_3_2 rw — DFE VGA stage 1 boost standard mode 2: This bit enables the active inductors boost function in stage 1 of the VGA, for high data rates, when xcvr_standard_mode is set to 2'b10.
  [17] RX_DIAG_DFE_AMP_TUNE_3_1 rw — DFE VGA stage 1 boost standard mode 1: This bit enables the active inductors boost function in stage 1 of the VGA, for high data rates, when xcvr_standard_mode is set to 2'b01.
  [16] RX_DIAG_DFE_AMP_TUNE_3_0 rw — DFE VGA stage 1 boost standard mode 0: This bit enables the active inductors boost function in stage 1 of the VGA, for high data rates, when xcvr_standard_mode is set to 2'b00.
  [15:14] RX_DIAG_DFE_AMP_TUNE_2_15_14 ro — Reserved
  [13:12] RX_DIAG_DFE_AMP_TUNE_2_13_12 rw — Receiver peaking amp common mode adjust: Adjusts the common mode voltage for the receiver peaking amp, by driving the rxda_fe_pkamp_cm_adj signal to the analog.
  [11] RX_DIAG_DFE_AMP_TUNE_2_11 rw — DFE low frequency equalizer constant gm bias enable: Enables the low frequency equalizer constant gm bias.
  [10:8] RX_DIAG_DFE_AMP_TUNE_2_10_8 rw — DFE low frequency equalizer current adjust: Adjusts the current for the DFE low frequency equalizer, using the rxda_lfeq_current_adj signal, as specified below.
  [7] RX_DIAG_DFE_AMP_TUNE_2_7 rw — DFE peaking amp boost: Enables the active inductors boost function in the peaking amp, for high data rates.
  [6] RX_DIAG_DFE_AMP_TUNE_2_6 rw — Reserved - Spare
  [5] RX_DIAG_DFE_AMP_TUNE_2_5 rw — DFE VGA stage 2 boost: Enables the active inductors boost function in stage 2 of the VGA, for high data rates.
  [4] RX_DIAG_DFE_AMP_TUNE_2_4 rw — DFE RX Tap 1 DAC Range Select: Controls the tap 1 DAC range in the analog DFE.
  [3:2] RX_DIAG_DFE_AMP_TUNE_2_3_2 ro — Reserved
  [1:0] RX_DIAG_DFE_AMP_TUNE_2_1_0 rw — DFE RX amp current adjust: Adjusts the mix of constant-gm and External Current for RX front end amplifiers.
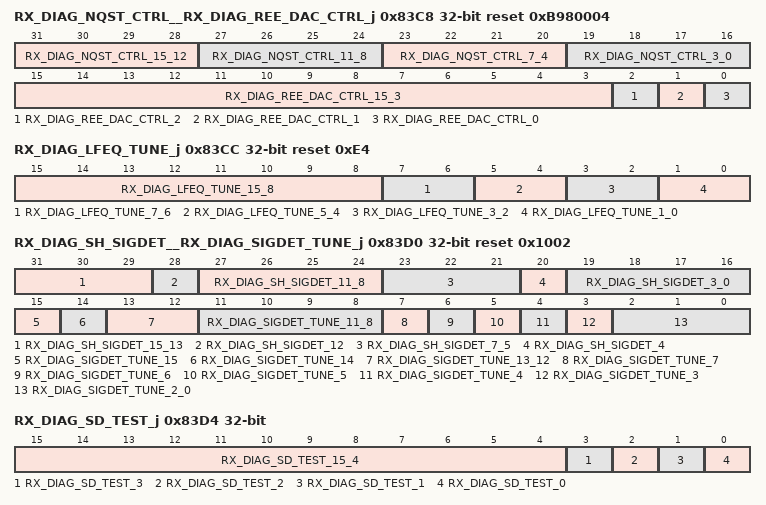
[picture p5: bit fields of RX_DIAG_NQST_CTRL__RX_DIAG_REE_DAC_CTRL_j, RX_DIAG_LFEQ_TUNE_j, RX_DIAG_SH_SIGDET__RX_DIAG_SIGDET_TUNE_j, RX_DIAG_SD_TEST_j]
0x83C8 RX_DIAG_NQST_CTRL__RX_DIAG_REE_DAC_CTRL_j reset 0xB980004 — REE DAC control register Offset = 83C8h + (j * 400h); where j = 0h to 3h
  [31:28] RX_DIAG_NQST_CTRL_15_12 rw — RX nyquist select value standard mode 3: This field specifies the receiver DFE nyquist frequency select value on the rxda_dfe_nqst_sel signal driven to the analog, when xcvr_standard_mode is set to 2'b11.
  [27:24] RX_DIAG_NQST_CTRL_11_8 rw — RX nyquist select value standard mode 2: This field specifies the receiver DFE nyquist frequency select value on the rxda_dfe_nqst_sel signal driven to the analog, when xcvr_standard_mode is set to 2'b10.
  [23:20] RX_DIAG_NQST_CTRL_7_4 rw — RX nyquist select value standard mode 1: This field specifies the receiver DFE nyquist frequency select value on the rxda_dfe_nqst_sel signal driven to the analog, when xcvr_standard_mode is set to 2'b01.
  [19:16] RX_DIAG_NQST_CTRL_3_0 rw — RX nyquist select value standard mode 0: This field specifies the receiver DFE nyquist frequency select value on the rxda_dfe_nqst_sel signal driven to the analog, when xcvr_standard_mode is set to 2'b00.
  [15:3] RX_DIAG_REE_DAC_CTRL_15_3 ro — Reserved
  [2] RX_DIAG_REE_DAC_CTRL_2 rw — DFE Offset DAC enable: Enables the DFE offset DAC associated with the VGA amp.
  [1] RX_DIAG_REE_DAC_CTRL_1 rw — DFE Offset DAC attenuation: Adds attenuation to the DFE offset DAC associated with the VGA amp.
  [0] RX_DIAG_REE_DAC_CTRL_0 rw — DFE DAC attenuation: Adds attenuation to the DFE DACs associated with the summing amp.
0x83CC RX_DIAG_LFEQ_TUNE_j reset 0xE4 — Low frequency equalizer tuning register Offset = 83CCh + (j * 400h); where j = 0h to 3h
  [15:8] RX_DIAG_LFEQ_TUNE_15_8 ro — Reserved
  [7:6] RX_DIAG_LFEQ_TUNE_7_6 rw — RX low frequency equalization zero frequency value standard mode 3: This field specifies the receiver zero frequency setting for the low frequency equalization function, by driving the rxda_dfe_lfeq_zero_freq signal going into the analog, when xcvr_standard_mode is set to 2'b11.
  [5:4] RX_DIAG_LFEQ_TUNE_5_4 rw — RX low frequency equalization zero frequency value standard mode 2: This field specifies the receiver zero frequency setting for the low frequency equalization function, by driving the rxda_dfe_lfeq_zero_freq signal going into the analog, when xcvr_standard_mode is set to 2'b10.
  [3:2] RX_DIAG_LFEQ_TUNE_3_2 rw — RX low frequency equalization zero frequency value standard mode 1: This field specifies the receiver zero frequency setting for the low frequency equalization function, by driving the rxda_dfe_lfeq_zero_freq signal going into the analog, when xcvr_standard_mode is set to 2'b01.
  [1:0] RX_DIAG_LFEQ_TUNE_1_0 rw — RX low frequency equalization zero frequency value standard mode 0: This field specifies the receiver zero frequency setting for the low frequency equalization function, by driving the rxda_dfe_lfeq_zero_freq signal going into the analog, when xcvr_standard_mode is set to 2'b00.
0x83D0 RX_DIAG_SH_SIGDET__RX_DIAG_SIGDET_TUNE_j reset 0x1002 — RX signal detect tuning and control register Offset = 83D0h + (j * 400h); where j = 0h to 3h
  [31:29] RX_DIAG_SH_SIGDET_15_13 ro — Reserved
  [28] RX_DIAG_SH_SIGDET_12 ro — Signal detect 1 up: Signal detect 1 calibration up signal value, as it is currently captured in the sample and hold latches.
  [27:24] RX_DIAG_SH_SIGDET_11_8 ro — Signal detect 1 code: Signal detect 1 calibration code signal value, as it is currently captured in the sample and hold latches.
  [23:21] RX_DIAG_SH_SIGDET_7_5 ro — Reserved
  [20] RX_DIAG_SH_SIGDET_4 ro — Signal detect 0 up: Signal detect 0 calibration up signal value, as it is currently captured in the sample and hold latches.
  [19:16] RX_DIAG_SH_SIGDET_3_0 ro — Signal detect 0 code: Signal detect 0 calibration code signal value, as it is currently captured in the sample and hold latches.
  [15] RX_DIAG_SIGDET_TUNE_15 ro — Reserved
  [14] RX_DIAG_SIGDET_TUNE_14 rw — Signal detect calibration half gain select: Controls the resolution of each step in the signal detect calibration code by adjusting the gain of signal detect offset correction, by driving the rxda_sd_cal_halfgain signal going to the analog, as specified below.
  [13:12] RX_DIAG_SIGDET_TUNE_13_12 rw — Signal detect filter function select: Selects which of the two RX signal detect filter functions are enabled.
  [11:8] RX_DIAG_SIGDET_TUNE_11_8 ro — Reserved
  [7] RX_DIAG_SIGDET_TUNE_7 rw — Receiver signal detect invert samplers: Inverts the behavior of the rxda_sd_pulse_high and rxda_sd_pulse_low samplers, by driving the rxda_sd_invert_samplers signal to the analog.
  [6] RX_DIAG_SIGDET_TUNE_6 rw — Receiver signal detect squelch pulse none: Enable the squelch function for the rxda_sd_pulse_none signal, by driving the rxda_sd_squelch_pulse_none signal to the analog.
  [5] RX_DIAG_SIGDET_TUNE_5 rw — Receiver signal detect one comparator mode: Enables one comparator mode, as a power reduction option, by driving the rxda_sd_onecomp_mode_en signal to the analog.
  [4] RX_DIAG_SIGDET_TUNE_4 rw — Receiver signal detect DC coupled path enable: Enables a DC coupled path to the signal detect for verification and testability purposes, by driving the rxda_sd_dcpath_en signal to the analog.
  [3] RX_DIAG_SIGDET_TUNE_3 ro — Reserved
  [2:0] RX_DIAG_SIGDET_TUNE_2_0 rw — Signal detect level: Sets the reference voltage level at which the comparators will detect a signal by driving the rxda_sd_siglvl_n signal going to the analog.
0x83D4 RX_DIAG_SD_TEST_j — Signal detect test register Offset = 83D4h + (j * 400h); where j = 0h to 3h
  [15:4] RX_DIAG_SD_TEST_15_4 ro — Reserved
  [3] RX_DIAG_SD_TEST_3 rw — LFPS detected low test bit: This bit can be used to detect if the rx_lfps_detect is driven to a low state.
  [2] RX_DIAG_SD_TEST_2 rw — LFPS detected high test bit: This bit can be used to detect if the rx_lfps_detect is driven to a high state.
  [1] RX_DIAG_SD_TEST_1 rw — Signal detected low test bit: This bit can be used to detect if the rx_signal_detect is driven to a low state.
  [0] RX_DIAG_SD_TEST_0 rw — Signal detected high test bit: This bit can be used to detect if the rx_signal_detect is driven to a high state.
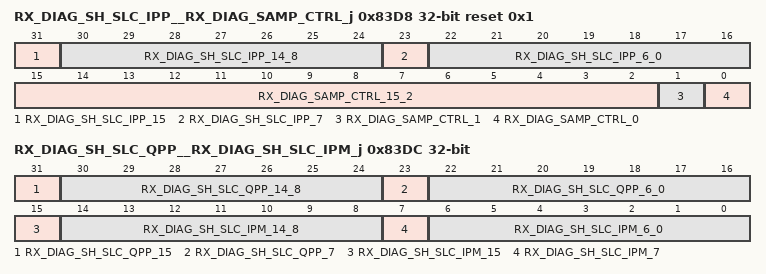
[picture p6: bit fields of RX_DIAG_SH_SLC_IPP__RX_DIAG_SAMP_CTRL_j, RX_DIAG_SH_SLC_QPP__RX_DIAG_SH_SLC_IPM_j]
0x83D8 RX_DIAG_SH_SLC_IPP__RX_DIAG_SAMP_CTRL_j reset 0x1 — RX sampler diagnostic control register Offset = 83D8h + (j * 400h); where j = 0h to 3h
  [31] RX_DIAG_SH_SLC_IPP_15 ro — Reserved
  [30:24] RX_DIAG_SH_SLC_IPP_14_8 ro — RX sampler latch calibration I even positive code: RX sampler latch calibration I even positive code signal value, as it is currently captured in the sample and hold latches.
  [23] RX_DIAG_SH_SLC_IPP_7 ro — Reserved
  [22:16] RX_DIAG_SH_SLC_IPP_6_0 ro — RX sampler latch calibration I odd positive code: RX sampler latch calibration I odd positive code signal value, as it is currently captured in the sample and hold latches.
  [15:2] RX_DIAG_SAMP_CTRL_15_2 ro — Reserved
  [1] RX_DIAG_SAMP_CTRL_1 rw — RX sampler latch range extend: Controls the range of the RX sampler calibration, by driving the rxda_sampler_latch_cal_range_ext signal to the analog.
  [0] RX_DIAG_SAMP_CTRL_0 rw — Analog sampler rxda_dfe_0p5ui_mode_en signal control: Selects which delayed I data is to be used to unroll the Q data in the sampler.
0x83DC RX_DIAG_SH_SLC_QPP__RX_DIAG_SH_SLC_IPM_j ro — Sample and hold RX sampler latch calibration I predictive negative code register Offset = 83DCh + (j * 400h); where j = 0h to 3h
  [31] RX_DIAG_SH_SLC_QPP_15 — Reserved
  [30:24] RX_DIAG_SH_SLC_QPP_14_8 — RX sampler latch calibration Q even positive code: RX sampler latch calibration Q even positive code signal value, as it is currently captured in the sample and hold latches.
  [23] RX_DIAG_SH_SLC_QPP_7 — Reserved
  [22:16] RX_DIAG_SH_SLC_QPP_6_0 — RX sampler latch calibration Q odd positive code: RX sampler latch calibration Q odd positive code signal value, as it is currently captured in the sample and hold latches.
  [15] RX_DIAG_SH_SLC_IPM_15 — Reserved
  [14:8] RX_DIAG_SH_SLC_IPM_14_8 — RX sampler latch calibration I even negative code: RX sampler latch calibration I even negative code signal value, as it is currently captured in the sample and hold latches.
  [7] RX_DIAG_SH_SLC_IPM_7 — Reserved
  [6:0] RX_DIAG_SH_SLC_IPM_6_0 — RX sampler latch calibration I odd negative code: RX sampler latch calibration I odd negative code signal value, as it is currently captured in the sample and hold latches.
